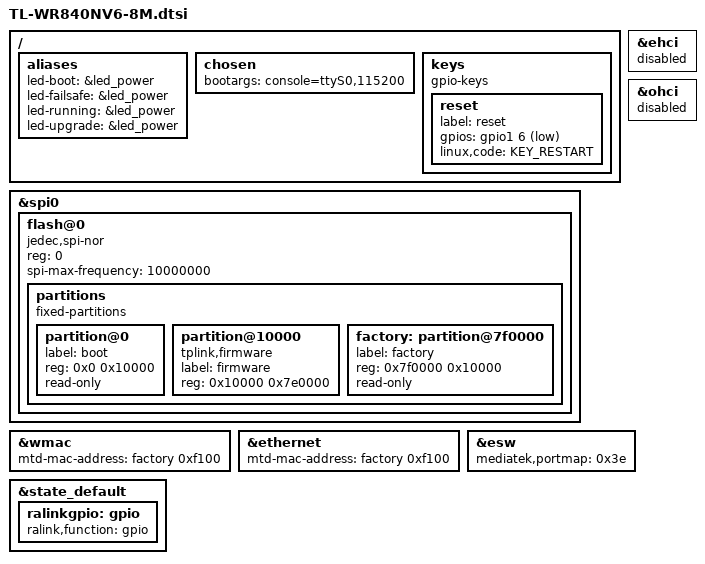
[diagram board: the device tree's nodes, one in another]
/dts-v1/;

#include "mt7628an.dtsi"

#include <dt-bindings/gpio/gpio.h>
#include <dt-bindings/input/input.h>

//This is to build a custom image to spi mod 8mb

/ {
	aliases {
		led-boot = &led_power;
		led-failsafe = &led_power;
		led-running = &led_power;
		led-upgrade = &led_power;
	};

	chosen {
		bootargs = "console=ttyS0,115200";
	};

	keys {
		compatible = "gpio-keys";

		reset {
			label = "reset";
			gpios = <&gpio1 6 GPIO_ACTIVE_LOW>;
			linux,code = <KEY_RESTART>;
		};
	};
};

&spi0 {
	status = "okay";

	flash@0 {
		compatible = "jedec,spi-nor";
		reg = <0>;
		spi-max-frequency = <10000000>;

		partitions {
			compatible = "fixed-partitions";
			#address-cells = <1>;
			#size-cells = <1>;

			partition@0 {
				label = "boot";
				reg = <0x0 0x10000>;
				read-only;
			};

			partition@10000 {
				compatible = "tplink,firmware";
				label = "firmware";
				reg = <0x10000 0x7e0000>;
			};

			factory: partition@7f0000 {
				label = "factory";
				reg = <0x7f0000 0x10000>;
				read-only;
			};
		};
	};
};

&ehci {
	status = "disabled";
};

&ohci {
	status = "disabled";
};

&wmac {
	status = "okay";
	mtd-mac-address = <&factory 0xf100>;
};

&ethernet {
	mtd-mac-address = <&factory 0xf100>;
};

&esw {
	mediatek,portmap = <0x3e>;
};

&state_default {
	ralinkgpio: gpio {
		ralink,function = "gpio";
	};
};
